# IND83215A register map
Series: Verne; File version: A0
CPU: CM0 r0p1, selectable endian, no MPU, no FPU, 4 interrupt priority bits
Registers are 32-bit, read-write, no defined reset value unless marked. A register's access mark holds for its fields unless they carry their own. Offsets are from the block's base; [hi:lo] are bit positions; {n}, {i} and the like mark numbered series.

## SAR_CTRL — SAR ADC Interface registers
Base 0x50013400; register names take the prefix SAR_CTRL_
0x00 DATA1 — Data Out of CH1,
  [15:0] DATA1 ro — The result of ADC conversion of CH1(in 2's-complement)
0x04 DATA2 — Data Out of CH2,
  [15:0] DATA2 ro — The result of ADC conversion of CH2(in 2's-complement)
0x08 DATA3 — Data Out of CH3,
  [15:0] DATA3 ro — The result of ADC conversion of CH3(in 2's-complement)
0x0C DATA4 — Data Out of CH4,
  [15:0] DATA4 ro — The result of ADC conversion of CH4(in 2's-complement)
0x10 DATA5 — Data Out of CH5,
  [15:0] DATA5 ro — The result of ADC conversion of CH5(in 2's-complement)
0x14 DATA6 — Data Out of CH6,
  [15:0] DATA6 ro — The result of ADC conversion of CH6(in 2's-complement)
0x18 DATA7 — Data Out of CH7,
  [15:0] DATA7 ro — The result of ADC conversion of CH7(in 2's-complement)
0x1C DATA8 — Data Out of CH8,
  [15:0] DATA8 ro — The result of ADC conversion of CH8(in 2's-complement)
0x20 DATA9 — Data Out of CH9,
  [15:0] DATA9 ro — The result of ADC conversion of CH9(in 2's-complement)
0x24 DATA10 — Data Out of CH10,
  [15:0] DATA10 ro — The result of ADC conversion of CH10(in 2's-complement)
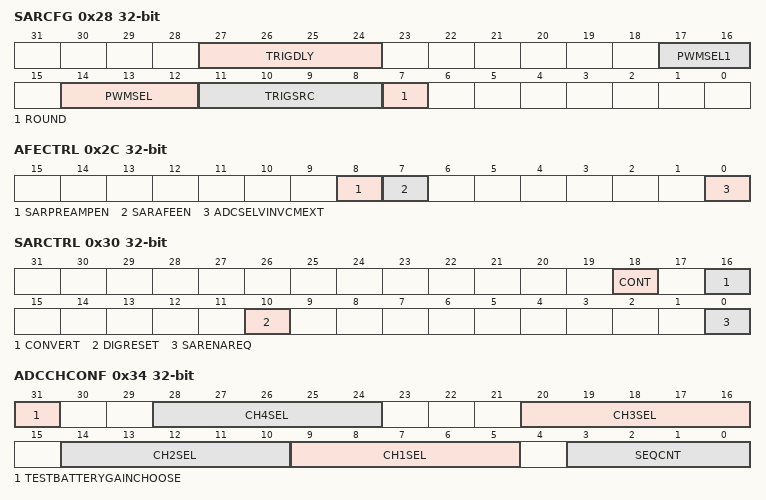
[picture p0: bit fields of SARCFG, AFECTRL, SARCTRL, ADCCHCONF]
0x28 SARCFG — SAR Configuration Register
  [27:24] TRIGDLY — trigger delay. setting trigger delay time from 0 to 15 sar clock cycles. For PN-detect, trigger delay MUST >= 2us.
  [17:16] PWMSEL1 — PWM Period Trigger Signal Selects. Selects the PWM Period trigger Source. 0x0: Triggered by PWM Period 0x1: Triggered by PWM Aux counter0 Period 0x2: Triggered by PWM Aux counter1 Period
  [14:12] PWMSEL — PWM Edge Trigger Signal Selects. Selects the PWM Edge trigger Source. 0x0: Triggered by PWM0 edge 0x1: Triggered by PWM1 edge 0x2: Triggered by PWM2 edge 0x3: Triggered by PWM AUX0 edge 0x4: Triggered by PWM AUX1 edge 0x5: Triggered by PWM AUX2 edge 0x6: Triggered by PWM AUX3 edge 0x7: Triggered by PWM AUX4 edge
  [11:8] TRIGSRC — SAR Converion Trigger Source Selects. Selects the trigger condition of SAR ADC. Don't change the bits during an ADC conversion sequence is ongoing. 0x0: Triggered through software writing 1 to conversion bit: CONVERT. 0x8: Triggered through hardware, either select from TRIGSRC[2:0] or from PWMAUX_TRIGSEL. TRIGSRC[2:0]=0x0: Triggered by the PWM compare trigger0. 0x9: TRIGSRC[2:0]=0x1: Triggered by the PWM compare trigger1. 0xa: TRIGSRC[2:0]=0x2: Triggered by PWM PCC3_1. 0xb: TRIGSRC[2:0]=0x3: Triggered by CT6OUT. 0xc: TRIGSRC[2:0]=0x4: Triggered by CT3OUT. 0xd: TRIGSRC[2:0]=0x5: Triggered by GT1ADCTRIG. 0xe: TRIGSRC[2:0]=0x6: Triggered by GT2ADCTRIG. 0xf: TRIGSRC[2:0]=0x7: Triggered by GT3ADCTRIG.
  [7] ROUND — ADC round enable. Enable ADC round. 0x0: No round. 0x1: Negative code+1
0x2C AFECTRL — SAR AFE Control
  [8] SARPREAMPEN — adc pre-amp enable. 0:disable, 1:enable
  [7] SARAFEEN — ADC AFE Enable. adc afe enable. If vinp, vinn and vin vcm all choose external, adc afe should be disabled: adc_adc_en=0, otherwise, adc afe must be enabled: adc_afe_en=1.
  [0] ADCSELVINVCMEXT — Select External Inputs to ADC. choose ADC input common voltage. 0: choose internal vin_vcm, equals to (vinp+vinn)/2; 1: choose external vin_vcm, for PN detect.
0x30 SARCTRL — SAR ADC Control
  [18] CONT — Continuous Conversion Enable. If this bit has been set before an ADC conversion sequence trigged by CONVERT bit or PWM signals, the sequence will be treated as a sequential conversion, rather than a single conversion.
  [16] CONVERT dual — ADC START/STATUS Register. If SOFTWARE trigger source is selected, set to start a conversion, If HARDWARE trigger source is selected, write to this field will be ignored. Read 1 indicates ADC conversion is active; Read 0 indicates ADC is in idle state.
  [10] DIGRESET wo — SAR Digital Part Reset. Resets SAR digital parts. Autoclear: includes a synchronous reset signal which clears the register on the cycle following write.
  [0] SARENAREQ — SAR ADC Enable. Set to enable the SAR analog & digital part
0x34 ADCCHCONF — ADC Channel Configuration
  [31] TESTBATTERYGAINCHOOSE — VBAT Gain Select. 0: gain=1/14, vbat max 30V/14=2.14v, under ADC vref=2.4v 1: gain=1/28, vbat max 30V/28=1.07v, under ADC vref=1.2v
  [28:24] CH4SEL — Channel4 Selection. Refer to Channel1 Selects.
  [20:16] CH3SEL — Channel3 Selection. Refer to Channel1 Selects.
  [14:10] CH2SEL — Channel2 Selection. Refer to Channel1 Selects.
  [9:5] CH1SEL — Channel1 Selection. Channel1 Selects. NOTE:When a GPIO pin is selected for passing adc signal, it is recommended configure it to input mode and clear the corresponding RE, PD and PU controls. 0x1: adc_vinp=adc_refp , adc_vinn=adc_refp (all shot to adc_ref(2.4V) for adc channel offset K) 0x2: adc_vinp=adc_refp , adc_vinn=vref_gnd (for adc channel +gain error K) 0x3: adc_vinp=vref_gnd , adc_vinn=adc_refp (for adc channel -gain error K) 0x4: adc_vinp=TempSensor , adc_vinn=vref_gnd 0x5: adc_vinp=VDD_1V5 , adc_vinn=vref_gnd 0x6: adc_vinp=VDD_3V3 (1/2) , adc_vinn=vref_gnd. If IOCTRL.GPIOCONSEL is set when measuring this channel, IOCTRL.GPIOCONREG[0] must also set. 0x7: adc_vinp=VDD_PRE5V (1/4) , adc_vinn=vref_gnd. If IOCTRL.GPIOCONSEL is set when measuring this channel, IOCTRL.GPIOCONREG[2] must also set. 0x8: adc_vinp=VBAT ACCURATE (gain selected by TEST_BATTERY_GAIN_CHOOSE), adc_vinn=vref_gnd 0x9: adc_vinp=CSA_Filter_OUT , adc_vinn=vref_gnd 0xa: adc_vinp=CSA_OUT , adc_vinn=vref_gnd 0xb: adc_vinp=PA2 , adc_vinn=vref_gnd 0xc: adc_vinp=PA3 , adc_vinn=vref_gnd 0xd: adc_vinp=PA4 , adc_vinn=vref_gnd 0xe: adc_vinp=PA5 , adc_vinn=vref_gnd 0xf: adc_vinp=PA6 , adc_vinn=vref_gnd 0x10: adc_vinp=PC3 , adc_vinn=vref_gnd 0x11: adc_vinp=PC4 , adc_vinn=vref_gnd 0x12: adc_vinp=PB0 , adc_vinn=vref_gnd 0x13: adc_vinp=PB1 , adc_vinn=vref_gnd 0x14: adc_vinp=PB2 , adc_vinn=vref_gnd 0x15: adc_vinp=PB3 , adc_vinn=vref_gnd 0x16: adc_vinp=PB4 , adc_vinn=vref_gnd 0x17: adc_vinp=PB5 , adc_vinn=vref_gnd 0x18: adc_vinp=PB6 , adc_vinn=vref_gnd 0x19: adc_vinp=PB7 , adc_vinn=vref_gnd 0x1a: adc_vinp=VDD_3V3_EXT (1/2) , adc_vinn=vref_gnd. If IOCTRL.GPIOCONSEL is set when measuring this channel, IOCTRL.GPIOCONREG[3] must also set.
  [3:0] SEQCNT — Channel Sequence count. Selects the sequence of channels to be converted 0x1: CH1 only 0x2: CH1->CH2 0x3: CH1->CH2->CH3 0x4: CH1->CH2->CH3->CH4 0x5: CH1 to CH5 sequentially 0x6: CH1 to CH6 sequentially 0x7: CH1 to CH7 sequentially 0x8: CH1 to CH8 sequentially 0x9: CH1 to CH9 sequentially 0xa: CH1 to CH10 sequentially
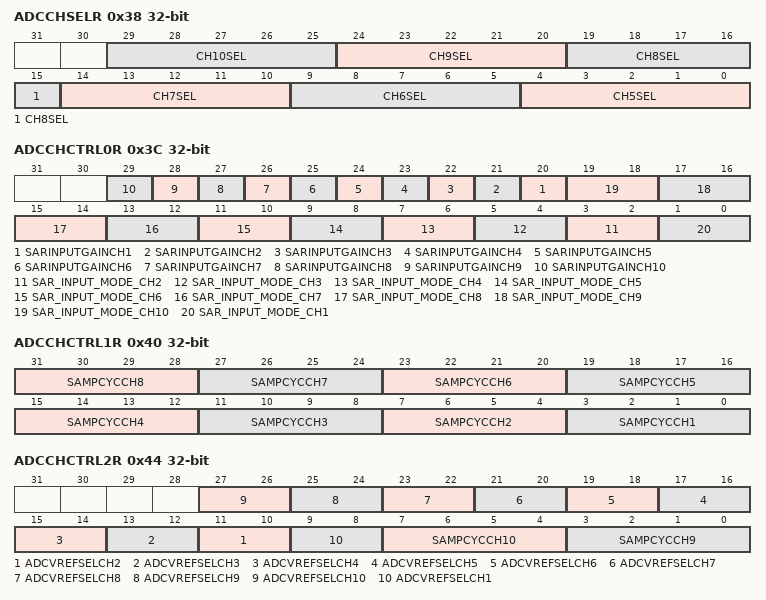
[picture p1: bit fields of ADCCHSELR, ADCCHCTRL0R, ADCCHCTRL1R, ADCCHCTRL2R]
0x38 ADCCHSELR — ADC Channel Selection Register
  [5n-21:5n-25] CH{n}SEL (n=5..10) — Channel{n} Selection. Refer to Channel1 Selects.
0x3C ADCCHCTRL0R — ADC Channel Control0 Register
  [n+19] SARINPUTGAINCH{n} (n=1..10) — ADC Channel{n} input gain. 0x0: 22/32 0x1: 31/32
  [2n-1:2n-2] SAR_INPUT_MODE_CH{n} (n=2..10) — CH{n} AFE Input Modes. ADC AFE Input Modes for Channel{n}.
  [1:0] SAR_INPUT_MODE_CH1 — CH1 AFE Input Modes. ADC AFE Input Modes for Channel1. 0x0: All external. 0x1: VINP buffered, VINN external. 0x2: VINN buffered, VINP external. 0x3: Both VINP & VINN buffered.
0x40 ADCCHCTRL1R — ADC Channel Control1 Register
  [4n-1:4n-4] SAMPCYCCH{n} (n=2..8) — Channel{n} Sample cycle. Refer to SAMPCYC_CH1.
  [3:0] SAMPCYCCH1 — Channel1 Sample cycle. setting sampling time from 1 to 16 sar clock cycles. 0x0: 1 Cycle 0x1: 2 Cycles 0x2: 3 Cycles ... 0xf: 16 Cycles
0x44 ADCCHCTRL2R — ADC Channel Control2 Register
  [2n+7:2n+6] ADCVREFSELCH{n} (n=2..10) — Channel{n} adc vref select. Refer to ADC_VREF_SEL_CH1.
  [9:8] ADCVREFSELCH1 — Channel1 adc vref select. 0x0: adc_vref = vbg 0x1: adc_vref = 2*vbg 0x2: adc_vref = VDD_3V3 0x3: adc_vref = VDD_3V3
  [7:4] SAMPCYCCH10 — Channel10 Sample cycle. Refer to SAMPCYC_CH1.
  [3:0] SAMPCYCCH9 — Channel9 Sample cycle. Refer to SAMPCYC_CH1.
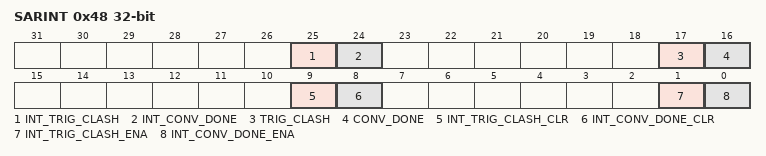
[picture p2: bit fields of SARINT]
0x48 SARINT — SAR Interrupts
  [25] INT_TRIG_CLASH ro — Trigger Clash Interrupt. Set by the SAR when TRIG_CLASH is high and INT_TRIG_CLASH_ENA is set
  [24] INT_CONV_DONE ro — Convert Done Interrupt. Set by the SAR when an convert done occurs
  [17] TRIG_CLASH ro — Trigger Clash. Set by the SAR when new trigger issued when previous has not finished.
  [16] CONV_DONE ro — Convert Done. Set by the SAR when an conversion is done.
  [9] INT_TRIG_CLASH_CLR wo — Trigger Clash Interrupt Clear.
  [8] INT_CONV_DONE_CLR wo — Convert Done Interrupt Clear. Autoclear: includes a synchronous reset signal which clears the register on the cycle following write.
  [1] INT_TRIG_CLASH_ENA — Trigger Clash Interrupt Enable.
  [0] INT_CONV_DONE_ENA — Convert Done Interrupt Enable.
0x4C SARCLKDIV — SAR CLOCK DIVIDE
  [7:0] SARCLKDIV — SAR CLOCK DIVIDE. Divide ration is (SAR_CLK_DIV+1)
